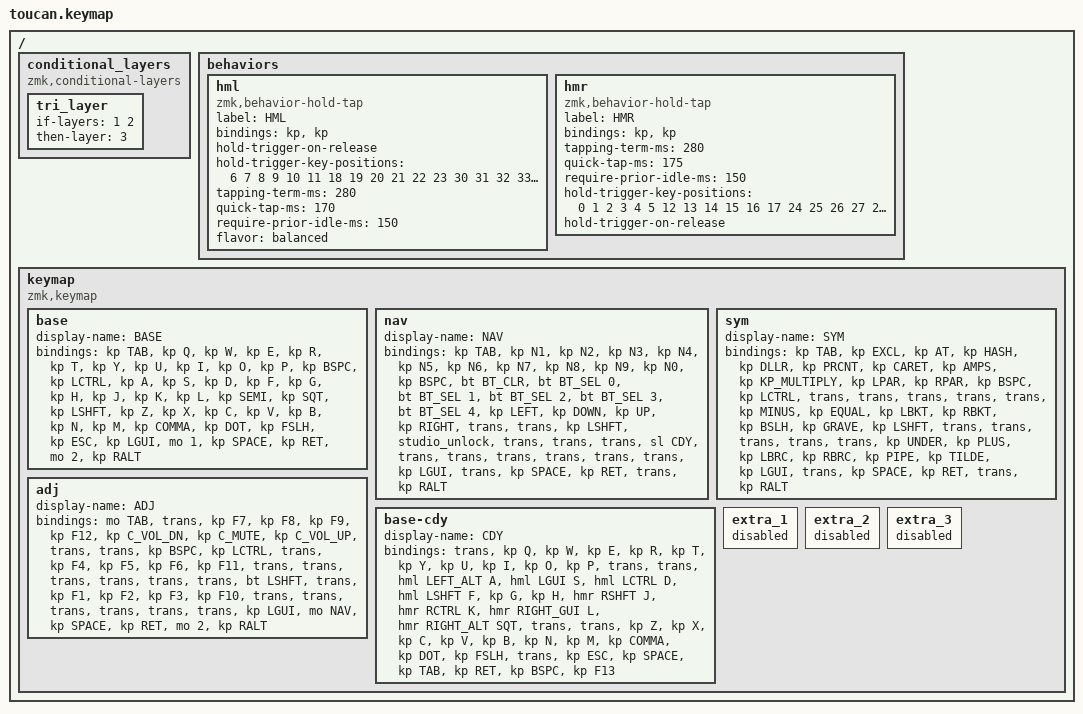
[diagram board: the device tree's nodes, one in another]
#include <behaviors.dtsi>
#include <dt-bindings/zmk/bt.h>
#include <dt-bindings/zmk/keys.h>

#include <dt-bindings/zmk/outputs.h>

#define BASE 0
#define NAV  1
#define SYM  2
#define ADJ  3
#define CDY  4

/ {
    conditional_layers {
        compatible = "zmk,conditional-layers";

        tri_layer {
            if-layers = <1 2>;
            then-layer = <3>;
        };
    };

    behaviors {
        hml: hml {
            compatible = "zmk,behavior-hold-tap";
            label = "HML";
            bindings = <&kp>, <&kp>;

            #binding-cells = <2>;
            hold-trigger-on-release;
            hold-trigger-key-positions = <6 7 8 9 10 11 18 19 20 21 22 23 30 31 32 33 34 35>;
            tapping-term-ms = <280>;
            quick-tap-ms = <170>;
            require-prior-idle-ms = <150>;
            flavor = "balanced";
        };

        hmr: hmr {
            compatible = "zmk,behavior-hold-tap";
            label = "HMR";
            bindings = <&kp>, <&kp>;

            #binding-cells = <2>;
            tapping-term-ms = <280>;
            quick-tap-ms = <175>;
            require-prior-idle-ms = <150>;
            hold-trigger-key-positions = <0 1 2 3 4 5 12 13 14 15 16 17 24 25 26 27 28 29>;
            hold-trigger-on-release;
        };
    };

    keymap {
        compatible = "zmk,keymap";

        base {
            display-name = "BASE";
            bindings = <
&kp TAB  &kp Q  &kp W  &kp E  &kp R  &kp T  &kp Y  &kp U  &kp I  &kp O  &kp P  &kp BSPC  &kp LCTRL  &kp A  &kp S  &kp D  &kp F  &kp G  &kp H  &kp J  &kp K  &kp L  &kp SEMI  &kp SQT  &kp LSHFT  &kp Z  &kp X  &kp C  &kp V  &kp B  &kp N  &kp M  &kp COMMA  &kp DOT  &kp FSLH  &kp ESC  &kp LGUI  &mo 1  &kp SPACE  &kp RET  &mo 2  &kp RALT
            >;
        };

        nav {
            display-name = "NAV";
            bindings = <
&kp TAB  &kp N1  &kp N2  &kp N3  &kp N4  &kp N5  &kp N6  &kp N7  &kp N8  &kp N9  &kp N0  &kp BSPC  &bt BT_CLR  &bt BT_SEL 0  &bt BT_SEL 1  &bt BT_SEL 2  &bt BT_SEL 3  &bt BT_SEL 4  &kp LEFT  &kp DOWN  &kp UP  &kp RIGHT  &trans  &trans  &kp LSHFT  &studio_unlock  &trans  &trans  &trans  &sl CDY  &trans  &trans  &trans  &trans  &trans  &trans  &kp LGUI  &trans  &kp SPACE  &kp RET  &trans  &kp RALT
            >;
        };

        sym {
            display-name = "SYM";
            bindings = <
&kp TAB  &kp EXCL  &kp AT  &kp HASH  &kp DLLR  &kp PRCNT  &kp CARET  &kp AMPS  &kp KP_MULTIPLY  &kp LPAR  &kp RPAR  &kp BSPC  &kp LCTRL  &trans  &trans  &trans  &trans  &trans  &kp MINUS  &kp EQUAL  &kp LBKT  &kp RBKT  &kp BSLH  &kp GRAVE  &kp LSHFT  &trans  &trans  &trans  &trans  &trans  &kp UNDER  &kp PLUS  &kp LBRC  &kp RBRC  &kp PIPE  &kp TILDE  &kp LGUI  &trans  &kp SPACE  &kp RET  &trans  &kp RALT
            >;
        };

        adj {
            display-name = "ADJ";
            bindings = <
&mo TAB  &trans  &kp F7  &kp F8  &kp F9  &kp F12  &kp C_VOL_DN  &kp C_MUTE  &kp C_VOL_UP  &trans  &trans  &kp BSPC  &kp LCTRL  &trans  &kp F4  &kp F5  &kp F6  &kp F11  &trans  &trans  &trans  &trans  &trans  &trans  &bt LSHFT  &trans  &kp F1  &kp F2  &kp F3  &kp F10  &trans  &trans  &trans  &trans  &trans  &trans  &kp LGUI  &mo NAV  &kp SPACE  &kp RET  &mo 2  &kp RALT
            >;
        };

        base-cdy {
            display-name = "CDY";
            bindings = <
&trans  &kp Q  &kp W  &kp E  &kp R  &kp T  &kp Y  &kp U  &kp I  &kp O  &kp P  &trans  &trans  &hml LEFT_ALT A  &hml LGUI S  &hml LCTRL D  &hml LSHFT F  &kp G  &kp H  &hmr RSHFT J  &hmr RCTRL K  &hmr RIGHT_GUI L  &hmr RIGHT_ALT SQT  &trans  &trans  &kp Z  &kp X  &kp C  &kp V  &kp B  &kp N  &kp M  &kp COMMA  &kp DOT  &kp FSLH  &trans  &kp ESC  &kp SPACE  &kp TAB  &kp RET  &kp BSPC  &kp F13
            >;
        };

        extra_1 { status = "reserved"; };

        extra_2 { status = "reserved"; };

        extra_3 { status = "reserved"; };
    };
};
